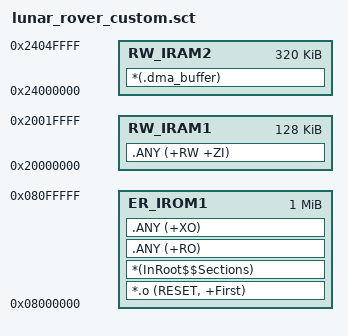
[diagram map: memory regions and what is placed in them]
; *************************************************************
; *** Custom scatter file for lunar_rover (H723, AC6) ***
; *************************************************************

LR_IROM1 0x08000000 0x00100000  {    ; load region size_region
  ER_IROM1 0x08000000 0x00100000  {  ; load address = execution address
   *.o (RESET, +First)
   *(InRoot$$Sections)
   .ANY (+RO)
   .ANY (+XO)
  }
  RW_IRAM2 0x24000000 0x00050000  {  ; AXI SRAM
   *(.dma_buffer)
  }
  RW_IRAM1 0x20000000 0x00020000  {  ; DTCM
   .ANY (+RW +ZI)
  }
}
